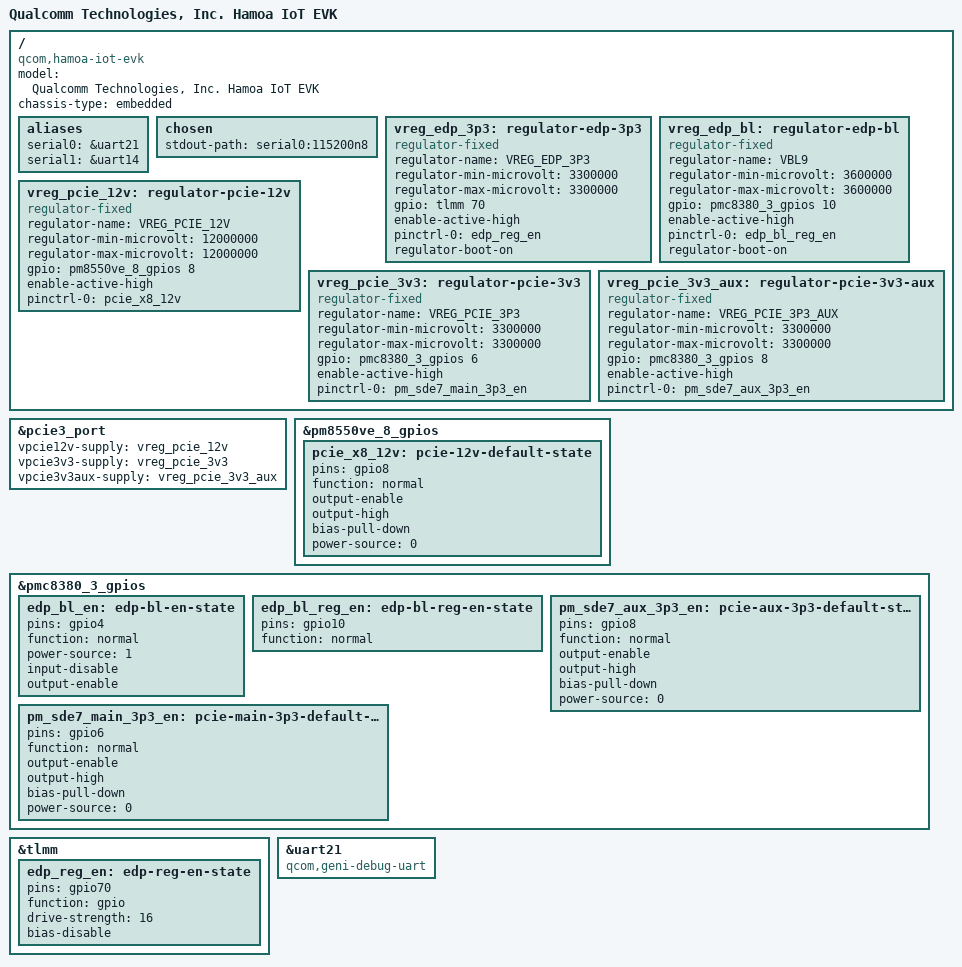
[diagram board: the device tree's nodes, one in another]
// SPDX-License-Identifier: BSD-3-Clause
/*
 * Copyright (c) Qualcomm Technologies, Inc. and/or its subsidiaries.
 */

/dts-v1/;

#include "hamoa-iot-come-som.dtsi"
#include <dt-bindings/pinctrl/qcom,pmic-gpio.h>

/ {
	model = "Qualcomm Technologies, Inc. Hamoa IoT EVK";
	compatible = "qcom,hamoa-iot-evk", "qcom,hamoa-iot-som", "qcom,x1e80100";
	chassis-type = "embedded";

	aliases {
		serial0 = &uart21;
		serial1 = &uart14;
	};

	chosen {
		stdout-path = "serial0:115200n8";
	};

	vreg_edp_3p3: regulator-edp-3p3 {
		compatible = "regulator-fixed";

		regulator-name = "VREG_EDP_3P3";
		regulator-min-microvolt = <3300000>;
		regulator-max-microvolt = <3300000>;

		gpio = <&tlmm 70 GPIO_ACTIVE_HIGH>;
		enable-active-high;

		pinctrl-0 = <&edp_reg_en>;
		pinctrl-names = "default";

		regulator-boot-on;
	};

	vreg_edp_bl: regulator-edp-bl {
		compatible = "regulator-fixed";

		regulator-name = "VBL9";
		regulator-min-microvolt = <3600000>;
		regulator-max-microvolt = <3600000>;

		gpio = <&pmc8380_3_gpios 10 GPIO_ACTIVE_HIGH>;
		enable-active-high;

		pinctrl-names = "default";
		pinctrl-0 = <&edp_bl_reg_en>;

		regulator-boot-on;
	};

	vreg_pcie_12v: regulator-pcie-12v {
		compatible = "regulator-fixed";

		regulator-name = "VREG_PCIE_12V";
		regulator-min-microvolt = <12000000>;
		regulator-max-microvolt = <12000000>;

		gpio = <&pm8550ve_8_gpios 8 GPIO_ACTIVE_HIGH>;
		enable-active-high;

		pinctrl-0 = <&pcie_x8_12v>;
		pinctrl-names = "default";
	};

	vreg_pcie_3v3: regulator-pcie-3v3 {
		compatible = "regulator-fixed";

		regulator-name = "VREG_PCIE_3P3";
		regulator-min-microvolt = <3300000>;
		regulator-max-microvolt = <3300000>;

		gpio = <&pmc8380_3_gpios 6 GPIO_ACTIVE_HIGH>;
		enable-active-high;

		pinctrl-0 = <&pm_sde7_main_3p3_en>;
		pinctrl-names = "default";
	};

	vreg_pcie_3v3_aux: regulator-pcie-3v3-aux {
		compatible = "regulator-fixed";

		regulator-name = "VREG_PCIE_3P3_AUX";
		regulator-min-microvolt = <3300000>;
		regulator-max-microvolt = <3300000>;

		gpio = <&pmc8380_3_gpios 8 GPIO_ACTIVE_HIGH>;
		enable-active-high;

		pinctrl-0 = <&pm_sde7_aux_3p3_en>;
		pinctrl-names = "default";
	};


};

&pcie3_port {
	vpcie12v-supply = <&vreg_pcie_12v>;
	vpcie3v3-supply = <&vreg_pcie_3v3>;
	vpcie3v3aux-supply = <&vreg_pcie_3v3_aux>;
};

&pm8550ve_8_gpios {
	pcie_x8_12v: pcie-12v-default-state {
		pins = "gpio8";
		function = "normal";
		output-enable;
		output-high;
		bias-pull-down;
		power-source = <0>;
	};
};

&pmc8380_3_gpios {
	edp_bl_en: edp-bl-en-state {
		pins = "gpio4";
		function = "normal";
		power-source = <1>;
		input-disable;
		output-enable;
	};

	edp_bl_reg_en: edp-bl-reg-en-state {
		pins = "gpio10";
		function = "normal";
	};

	pm_sde7_aux_3p3_en: pcie-aux-3p3-default-state {
		pins = "gpio8";
		function = "normal";
		output-enable;
		output-high;
		bias-pull-down;
		power-source = <0>;
	};

	pm_sde7_main_3p3_en: pcie-main-3p3-default-state {
		pins = "gpio6";
		function = "normal";
		output-enable;
		output-high;
		bias-pull-down;
		power-source = <0>;
	};
};

&tlmm {
	edp_reg_en: edp-reg-en-state {
		pins = "gpio70";
		function = "gpio";
		drive-strength = <16>;
		bias-disable;
	};
};

&uart21 {
	compatible = "qcom,geni-debug-uart";

	status = "okay";
};
